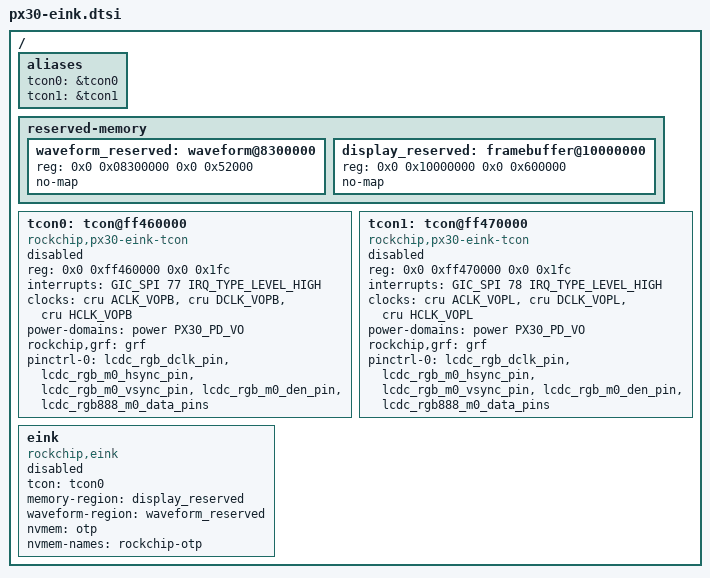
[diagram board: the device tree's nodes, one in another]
/*
 * Copyright (c) 2017 Fuzhou Rockchip Electronics Co., Ltd
 *
 * SPDX-License-Identifier: (GPL-2.0+ OR MIT)
 */

/ {
	aliases {
		tcon0 = &tcon0;
		tcon1 = &tcon1;
	};

	reserved-memory {
		// 20190906: waveform 的大小固定的，不会超过 312K， 
		// --尝试把地址改为 0x08800000 ,内核跑不起来。访问虚拟地址的时候挂掉了。
		// --U-BOOT 里面规定死了，waveform 的保留起始地址是 waveform_add_r=0x08300000 
		// (include/configs/px30_common.h),且长度是 EINK_WAVEFORM_SIZE	512000 。这部分
		// 的空间必须留出来，否则对应部分的内核数据就会被覆盖。--后面修改我们自己的U-BOOT数据
		// 之后，再修改这部分区间和大小。
		waveform_reserved: waveform@8300000 {
			reg = <0x0 0x08300000 0x0 0x52000>;
			no-map;
		};

		display_reserved: framebuffer@10000000 {
			reg = <0x0 0x10000000 0x0 0x600000>;
			no-map;
		};
		
		// 20190909,hsl add for debug.
		/*dumpfs_reserved: dumpfs@11000000 {
			reg = <0x0 0x11000000 0x0 0x600000>;
			no-map;
		};*/
	};

	tcon0: tcon@ff460000 {
		compatible = "rockchip,px30-eink-tcon";
		reg = <0x0 0xff460000 0x0 0x1fc>;
		interrupts = <GIC_SPI 77 IRQ_TYPE_LEVEL_HIGH>;
		clocks = <&cru ACLK_VOPB>, <&cru DCLK_VOPB>,
			 <&cru HCLK_VOPB>;
		clock-names = "aclk", "dclk", "hclk";
		power-domains = <&power PX30_PD_VO>;
		rockchip,grf = <&grf>;

		pinctrl-names = "default";
		pinctrl-0 = <&lcdc_rgb_dclk_pin
			     &lcdc_rgb_m0_hsync_pin
			     &lcdc_rgb_m0_vsync_pin
			     &lcdc_rgb_m0_den_pin
			     &lcdc_rgb888_m0_data_pins>;
		status = "disabled";
	};

	tcon1: tcon@ff470000 {
		compatible = "rockchip,px30-eink-tcon";
		reg = <0x0 0xff470000 0x0 0x1fc>;
		interrupts = <GIC_SPI 78 IRQ_TYPE_LEVEL_HIGH>;
		clocks = <&cru ACLK_VOPL>, <&cru DCLK_VOPL>,
			 <&cru HCLK_VOPL>;
		clock-names = "aclk", "dclk", "hclk";
		power-domains = <&power PX30_PD_VO>;
		rockchip,grf = <&grf>;

		pinctrl-names = "default";
		pinctrl-0 = <&lcdc_rgb_dclk_pin
			     &lcdc_rgb_m0_hsync_pin
			     &lcdc_rgb_m0_vsync_pin
			     &lcdc_rgb_m0_den_pin
			     &lcdc_rgb888_m0_data_pins>;
		status = "disabled";
	};

	eink: eink {
		compatible = "rockchip,eink";
		tcon = <&tcon0>;
		memory-region = <&display_reserved>;
		waveform-region = <&waveform_reserved>;
		nvmem = <&otp>;
		nvmem-names = "rockchip-otp";
		status = "disabled";
	};
};
